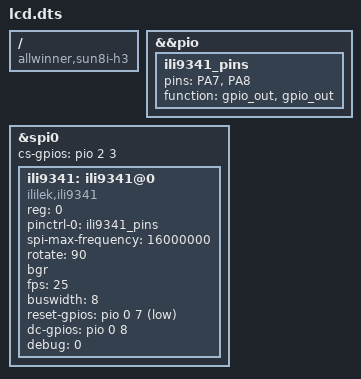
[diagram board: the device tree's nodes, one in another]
/dts-v1/;
/plugin/;

/ {
	compatible = "allwinner,sun8i-h3";

  fragment@0 {
  
    target-path = "&pio";
    __overlay__ {
      ili9341_pins: ili9341_pins {
        pins = "PA7", "PA8"; /*RESET, DC_RS*/
        function = "gpio_out", "gpio_out" ;
      };
    };
  };

  fragment@1 {
    target = <&spi0>;
    __overlay__ {
		#address-cells = <0x01>;
		#size-cells = <0x00>;
      status = "okay";
      cs-gpios = <&pio 2 3 0>; /* PC3 */

      ili9341: ili9341@0 {
        compatible = "ililek,ili9341";
        reg = <0>;
        pinctrl-names = "default";
        pinctrl-0 = <&ili9341_pins>;
        spi-max-frequency = <16000000>;
        rotate = <90>;
        bgr;
        fps = <25>;
        buswidth = <8>;
        reset-gpios = <&pio 0 7 1>; /*RESET=PA7*/
        dc-gpios = <&pio 0 8 0>; /*DC_RS=PA8*/
        debug = <0>;
      };
    };
  };
};
